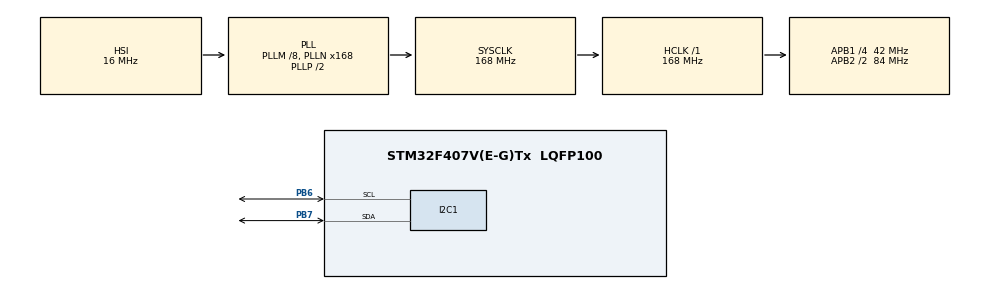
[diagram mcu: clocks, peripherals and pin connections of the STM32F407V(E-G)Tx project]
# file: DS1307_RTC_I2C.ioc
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Mcu.Family=STM32F4
Mcu.Name=STM32F407V(E-G)Tx
Mcu.Package=LQFP100
NVIC.PriorityGroup=NVIC_PRIORITYGROUP_0
PB6.Mode=I2C
PB6.Signal=I2C1_SCL
PB7.Mode=I2C
PB7.Signal=I2C1_SDA
ProjectManager.HeapSize=0x200
ProjectManager.StackSize=0x400
ProjectManager.TargetToolchain=STM32CubeIDE
RCC.48MHZClocksFreq_Value=48000000
RCC.AHBFreq_Value=168000000
RCC.APB1CLKDivider=RCC_HCLK_DIV4
RCC.APB1Freq_Value=42000000
RCC.APB1TimFreq_Value=84000000
RCC.APB2CLKDivider=RCC_HCLK_DIV2
RCC.APB2Freq_Value=84000000
RCC.APB2TimFreq_Value=168000000
RCC.CortexFreq_Value=168000000
RCC.HCLKFreq_Value=168000000
RCC.HSE_VALUE=8000000
RCC.HSI_VALUE=16000000
RCC.PLLM=8
RCC.PLLN=168
RCC.PLLQ=7
RCC.SYSCLKFreq_VALUE=168000000
RCC.SYSCLKSource=RCC_SYSCLKSOURCE_PLLCLK
RCC.VCOOutputFreq_Value=336000000
board=STM32F407G-DISC1

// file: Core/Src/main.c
/* USER CODE BEGIN Header */
/**
  ******************************************************************************
  * @file           : main.c
  * @brief          : Main program body
  ******************************************************************************
  * @attention
  *
  * Copyright (c) 2024 STMicroelectronics.
  * All rights reserved.
  *
  * This software is licensed under terms that can be found in the LICENSE file
  * in the root directory of this software component.
  * If no LICENSE file comes with this software, it is provided AS-IS.
  *
  ******************************************************************************
  */
/* USER CODE END Header */
#include "main.h"

/* USER CODE BEGIN PD */

#define DS1307_ADDRESS (0x68 << 1)  // Define DS1307 I2C address

/* USER CODE END PD */

I2C_HandleTypeDef hi2c1;  // I2C handle for communication

/* USER CODE BEGIN PV */

uint8_t  write_time_date[7];    // Buffer to store time data for writing
uint8_t read_time_date[7];    // Buffer to store time data read from DS1307
uint8_t bcd_time_date[7];    // Buffer to store time data in BCD format

/* USER CODE END PV */

void SystemClock_Config(void);    // Function to configure system clock
static void MX_GPIO_Init(void);   // Function to initialize GPIO
static void MX_I2C1_Init(void);    // Function to initialize I2C1

/* USER CODE BEGIN 0 */

// Convert decimal to BCD (Binary-Coded Decimal)
uint8_t DS1307_DEC2BCD(uint8_t dec) {
    return ((dec / 10) << 4) | (dec % 10);
}

// Convert BCD to decimal
uint8_t DS1307_BCD2DEC(uint8_t bcd) {
    return ((bcd >> 4) * 10) + (bcd & 0x0F);
}

// Set the time on the DS1307 RTC
void DS1307_SetTime(uint8_t year, uint8_t month, uint8_t date,uint8_t day,uint8_t hour, uint8_t minute, uint8_t second)
{
    write_time_date[0] = DS1307_DEC2BCD(second);  // Convert seconds to BCD
    write_time_date[1] = DS1307_DEC2BCD(minute);  // Convert minutes to BCD
    write_time_date[2] = DS1307_DEC2BCD(hour);    // Convert hours to BCD
    write_time_date[3] = DS1307_DEC2BCD(day);    // Convert hours to BCD
    write_time_date[4] = DS1307_DEC2BCD(date);    // Convert hours to BCD
    write_time_date[5] = DS1307_DEC2BCD(month);    // Convert hours to BCD
    write_time_date[6] = DS1307_DEC2BCD(year);    // Convert hours to BCD

    HAL_I2C_Mem_Write(&hi2c1, DS1307_ADDRESS, 0x00, I2C_MEMADD_SIZE_8BIT, write_time_date, 7, HAL_MAX_DELAY);  // Write time data to DS1307
}

// Get the time from the DS1307 RTC
void DS1307_GetTime() {
    HAL_I2C_Mem_Read(&hi2c1, DS1307_ADDRESS, 0x00, I2C_MEMADD_SIZE_8BIT, bcd_time_date, 7, HAL_MAX_DELAY);  // Read time data from DS1307
    for(int i = 0; i < 7; i++)
    {
        read_time_date[i] = DS1307_BCD2DEC(bcd_time_date[i]);  // Convert BCD data to decimal
    }
}

/* USER CODE END 0 */

int main(void)
{

  /* MCU Configuration--------------------------------------------------------*/

  /* Reset of all peripherals, Initializes the Flash interface and the Systick. */
  HAL_Init();  // Initialize the HAL Library

  /* Configure the system clock */
  SystemClock_Config();  // Configure system clock

  /* Initialize all configured peripherals */

  MX_GPIO_Init();  // Initialize GPIO
  MX_I2C1_Init();  // Initialize I2C1

  /* USER CODE BEGIN 2 */

  DS1307_SetTime(24, 12, 31, 3, 23, 59, 40); //YY-MM-DD-DAY-HR-MIN-SEC

  /* USER CODE END 2 */

  /* Infinite loop */
  while (1)
  {

    DS1307_GetTime();  // Get time

  }
}

void SystemClock_Config(void)
{
  RCC_OscInitTypeDef RCC_OscInitStruct = {0};
  RCC_ClkInitTypeDef RCC_ClkInitStruct = {0};

  /** Configure the main internal regulator output voltage
  */
  __HAL_RCC_PWR_CLK_ENABLE();  // Enable Power Control Clock
  __HAL_PWR_VOLTAGESCALING_CONFIG(PWR_REGULATOR_VOLTAGE_SCALE1);  // Set voltage scaling

  /** Initializes the RCC Oscillators according to the specified parameters
  * in the RCC_OscInitTypeDef structure.
  */
  RCC_OscInitStruct.OscillatorType = RCC_OSCILLATORTYPE_HSI;  // Use High-Speed Internal oscillator
  RCC_OscInitStruct.HSIState = RCC_HSI_ON;  // Turn on HSI
  RCC_OscInitStruct.HSICalibrationValue = RCC_HSICALIBRATION_DEFAULT;  // Default calibration value
  RCC_OscInitStruct.PLL.PLLState = RCC_PLL_ON;  // Turn on PLL
  RCC_OscInitStruct.PLL.PLLSource = RCC_PLLSOURCE_HSI;  // Use HSI as PLL source
  RCC_OscInitStruct.PLL.PLLM = 8;  // PLL M divider
  RCC_OscInitStruct.PLL.PLLN = 168;  // PLL N multiplier
  RCC_OscInitStruct.PLL.PLLP = RCC_PLLP_DIV2;  // PLL P divider
  RCC_OscInitStruct.PLL.PLLQ = 7;  // PLL Q divider
  if (HAL_RCC_OscConfig(&RCC_OscInitStruct) != HAL_OK)  // Initialize oscillators
  {
    Error_Handler();  // Call error handler if initialization fails
  }

  /** Initializes the CPU, AHB and APB buses clocks
  */
  RCC_ClkInitStruct.ClockType = RCC_CLOCKTYPE_HCLK|RCC_CLOCKTYPE_SYSCLK
                              |RCC_CLOCKTYPE_PCLK1|RCC_CLOCKTYPE_PCLK2;  // Configure clock types
  RCC_ClkInitStruct.SYSCLKSource = RCC_SYSCLKSOURCE_PLLCLK;  // Set PLL as SYSCLK source
  RCC_ClkInitStruct.AHBCLKDivider = RCC_SYSCLK_DIV1;  // AHB clock divider
  RCC_ClkInitStruct.APB1CLKDivider = RCC_HCLK_DIV4;  // APB1 clock divider
  RCC_ClkInitStruct.APB2CLKDivider = RCC_HCLK_DIV2;  // APB2 clock divider

  if (HAL_RCC_ClockConfig(&RCC_ClkInitStruct, FLASH_LATENCY_5) != HAL_OK)  // Configure CPU, AHB and APB clocks
  {
    Error_Handler();  // Call error handler if configuration fails
  }
}

static void MX_I2C1_Init(void)
{

  hi2c1.Instance = I2C1;  // Initialize I2C1
  hi2c1.Init.ClockSpeed = 100000;  // Set clock speed
  hi2c1.Init.DutyCycle = I2C_DUTYCYCLE_2;  // Set duty cycle
  hi2c1.Init.OwnAddress1 = 0;  // Set own address
  hi2c1.Init.AddressingMode = I2C_ADDRESSINGMODE_7BIT;  // Set addressing mode
  hi2c1.Init.DualAddressMode = I2C_DUALADDRESS_DISABLE;  // Disable dual address mode
  hi2c1.Init.OwnAddress2 = 0;  // Set second own address
  hi2c1.Init.GeneralCallMode = I2C_GENERALCALL_DISABLE;  // Disable general call mode
  hi2c1.Init.NoStretchMode = I2C_NOSTRETCH_DISABLE;  // Disable clock stretching
  if (HAL_I2C_Init(&hi2c1) != HAL_OK)  // Initialize I2C1
  {
    Error_Handler();  // Call error handler if initialization fails
  }

}

static void MX_GPIO_Init(void)
{

  /* GPIO Ports Clock Enable */
  __HAL_RCC_GPIOB_CLK_ENABLE();  // Enable GPIOB clock

}

void Error_Handler(void)
{
  /* USER CODE BEGIN Error_Handler_Debug */
  /* User can add his own implementation to report the HAL error return state */
  __disable_irq();  // Disable interrupts
  while (1)
  {
  }
  /* USER CODE END Error_Handler_Debug */
}
